AUTOSAR XML (schema 4.0)
package /ComponentTypes
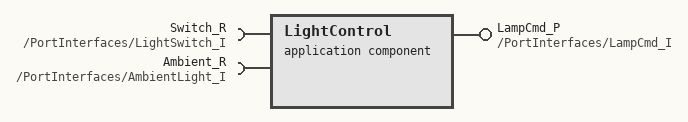
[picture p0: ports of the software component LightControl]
  application sw component type LightControl
    require port Switch_R: required-interface=/PortInterfaces/LightSwitch_I
    require port Ambient_R: required-interface=/PortInterfaces/AmbientLight_I
    provide port LampCmd_P: provided-interface=/PortInterfaces/LampCmd_I
  application sw component type SwitchReader
    provide port Switch_P: provided-interface=/PortInterfaces/LightSwitch_I
  application sw component type LampDriver
    require port LampCmd_R: required-interface=/PortInterfaces/LampCmd_I
